# NAVSS0_TIMERMGR_1_ALIAS64K_TIMERMGR1_CFG_TIMERS register map
Vendor: Texas Instruments
Peripheral module from a debugger description file (folder J721S2).
Registers are 32-bit, read-write, reset 0x0 unless marked. A register's access mark holds for its fields unless they carry their own. Offsets are as the file gives them; lines under a group give offsets from that group; [hi:lo] are bit positions; {n}, {i} and the like mark numbered series; 'fields as' and 'values as' point back to an identical list; <NAME> marks a mode.

## NAVSS0_TIMERMGR_1_ALIAS64K_TIMERMGR1_CFG_TIMERS
0x00 ALIAS64K_TIMERMGR1__CFG__TIMERS_TIMER_SETUP_VALUE — This reprograms timer N with the written value. This number will be the number of ticks of the timer_clock before the timer expires, if timer N and the timer manager itself are both enabled via TM_CTRL and TIMER_CONTROL_N
  [31:0] COUNT — The number of ticks of the timer_clock before this timer would expire when reprogrammed
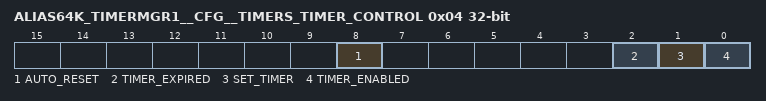
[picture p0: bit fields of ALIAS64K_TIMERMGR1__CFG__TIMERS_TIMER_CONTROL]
0x04 ALIAS64K_TIMERMGR1__CFG__TIMERS_TIMER_CONTROL access per field — Modifies the behavior of timer N with control signals below
  [8] AUTO_RESET rw — Automatically reset the timer when it expires. Provides the option of a periodic timer, rather than one that needs to be cleared after each expiration. Added for hardware usage of the timers, so the expirations can occur regularly without software reprogramming them.
  [2] TIMER_EXPIRED ro — The status of the current timer. 1 = expired
  [1] SET_TIMER wo — This may be used to touch/set a timer. When a 1 is written, the corresponding timer will be refreshed with the current value in its TIMER_SETUP_VALUES register. Will always read 0
  [0] TIMER_ENABLED rw — Write 1 to enable, 0 to disable the timer.
